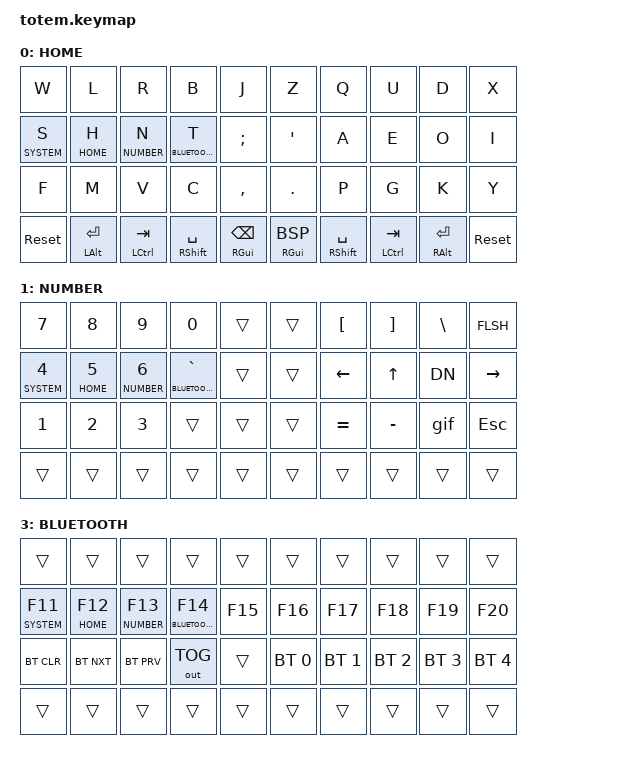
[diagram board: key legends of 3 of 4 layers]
//
//                                                        ▀▀▀▀▀     ▀▀▀▀▀          ▀▀█▀▀
//                                                        ▄▀▀▀▄  ▄  ▄▀▀▀▄  ▄  ▄▀▀▀▄  █  ▄▀▀▀▄
//                                                        █   █  █  █   █  █  █   █  █  █   █
//                                                         ▀▀▀   █   ▀▀▀   █   ▀▀▀   ▀   ▀▀▀
//                                                               █      ▄▄▄█▄▄▄    █   █  
//                                                               ▀      █  █  █     █▄█
//                                                             ▀▀▀▀▀    █  █  █      ▀
//                                                                      ▀  ▀  ▀
//
// ▄▄▄▄▄▄▄▄▄▄▄▄▄▄▄▄▄▄▄▄▄▄▄▄▄▄▄▄▄▄▄▄▄▄▄▄▄▄▄▄▄▄▄▄▄▄▄▄▄▄▄▄▄▄▄▄▄▄▄▄▄▄▄▄▄▄▄▄▄▄▄▄▄▄▄▄▄▄▄▄▄▄▄▄▄▄▄▄▄▄▄▄▄▄▄▄▄▄▄▄▄▄▄▄▄▄▄▄▄▄▄▄▄▄▄▄▄▄▄▄▄▄▄▄▄▄▄▄▄▄▄▄▄▄▄▄▄▄▄▄▄▄▄▄▄▄▄▄▄
       

#include <behaviors.dtsi>
#include <dt-bindings/zmk/keys.h>
#include <dt-bindings/zmk/bt.h>
#include <dt-bindings/zmk/outputs.h>

#define HOME 0
#define NUMBER 1
#define SYSTEM 2
#define BLUETOOTH 3

&mt {
  quick-tap-ms = <100>;
  global-quick-tap;
  flavor = "tap-preferred";
  tapping-term-ms = <170>;
};

/ {
    combos {
            compatible = "zmk,combos";
            combo_esc {
                timeout-ms = <50>;
                key-positions = <0 1>;
                bindings = <&kp ESC>;
            };
    };

    macros {
        gif: gif {
            label = "giphy";
            compatible = "zmk,behavior-macro";
            #binding-cells = <0>;
            bindings
                = <&macro_press &kp LSHFT>
                , <&macro_tap &kp N2>
                , <&macro_release &kp LSHFT>
                , <&macro_tap &kp G &kp I &kp F>
                ;
        };
    };

        keymap {
                compatible = "zmk,keymap";
// ▄▄▄▄▄▄▄▄▄▄▄▄▄▄▄▄▄▄▄▄▄▄▄▄▄▄▄▄▄▄▄▄▄▄▄▄▄▄▄▄▄▄▄▄▄▄▄▄▄▄▄▄▄▄▄▄▄▄▄▄▄▄▄▄▄▄▄▄▄▄▄▄▄▄▄▄▄▄▄▄▄▄▄▄▄▄▄▄▄▄▄▄▄▄▄▄▄▄▄▄▄▄▄▄▄▄▄▄▄▄▄▄▄▄▄▄▄▄▄▄▄▄▄▄▄▄▄▄▄▄▄▄▄▄▄▄▄▄▄▄▄▄▄▄▄▄▄▄▄

                home_layer {
// ┏━━━━━━━━━━━━━━━━━━━━━━━━━━━━━━━━━━━━━━━┓
label= "HOME"                              ;
// ┗━━━━━━━━━━━━━━━━━━━━━━━━━━━━━━━━━━━━━━━┛
//             ┏━━━━━━━━━━━┳━━━━━━━━━━━┳━━━━━━━━━━━┳━━━━━━━━━━━┳━━━━━━━━━━━┓   ┏━━━━━━━━━━━┳━━━━━━━━━━━┳━━━━━━━━━━━┳━━━━━━━━━━━┳━━━━━━━━━━━┓
//             ┃      W    ┃     L     ┃    R      ┃     B     ┃     J     ┃   ┃      Z    ┃   Q       ┃     U     ┃     D     ┃   X       ┃
//             ┣━━━━━━━━━━━╋━━━━━━━━━━━╋━━━━━━━━━━━╋━━━━━━━━━━━╋━━━━━━━━━━━┫   ┣━━━━━━━━━━━╋━━━━━━━━━━━╋━━━━━━━━━━━╋━━━━━━━━━━━╋━━━━━━━━━━━┫
//             ┃      S    ┃     H     ┃    N      ┃     T     ┃   ;       ┃   ┃    APOS   ┃   A       ┃     E     ┃     I     ┃     O     ┃
// ┏━━━━━━━━━━━╋━━━━━━━━━━━╋━━━━━━━━━━━╋━━━━━━━━━━━╋━━━━━━━━━━━╋━━━━━━━━━━━┫   ┣━━━━━━━━━━━╋━━━━━━━━━━━╋━━━━━━━━━━━╋━━━━━━━━━━━╋━━━━━━━━━━━╋━━━━━━━━━━━┓
// ┃           ┃      F    ┃     M     ┃    V      ┃     C     ┃    ,      ┃   ┃   .       ┃   P       ┃     G     ┃    K      ┃    Y      ┃           ┃
// ┗━━━━━━━━━━━┻━━━━━━━━━━━┻━━━━━━━━━━━╋━━━━━━━━━━━╋━━━━━━━━━━━╋━━━━━━━━━━━┫   ┣━━━━━━━━━━━╋━━━━━━━━━━━╋━━━━━━━━━━━╋━━━━━━━━━━━┻━━━━━━━━━━━┻━━━━━━━━━━━┛
//               sys_reset   ALT RET   ┃ LCTRL TAB ┃RSHFT SPACE┃ RGUI BSP  ┃   ┃  RGUI BSP ┃RSHFT SPACE┃ LCTRL TAB ┃ALT RET     sys_reset
//                                   ┗━━━━━━━━━━━┻━━━━━━━━━━━┻━━━━━━━━━━━┛   ┗━━━━━━━━━━━┻━━━━━━━━━━━┻━━━━━━━━━━━┛
 bindings = <
// ╷           ╷             ╷             ╷               ╷                 ╷           ╷     ╷             ╷               ╷             ╷             ╷           ╷

                &kp W          &kp L         &kp R          &kp B             &kp J             &kp Z         &kp Q           &kp U         &kp D        &kp X
                &lt SYSTEM S   &lt HOME H    &lt NUMBER N   &lt BLUETOOTH T   &kp SEMI          &kp APOS      &kp A           &kp E         &kp O        &kp I  
                &kp F          &kp M         &kp  V         &kp C             &kp COMMA         &kp DOT       &kp P           &kp G         &kp K        &kp Y
                &sys_reset     &mt LALT RET  &mt LCTRL TAB  &mt RSHFT SPACE   &mt RGUI BSPC     &mt RGUI BSP  &mt RSHFT SPACE &mt LCTRL TAB &mt RALT RET &sys_reset 
                        >;
                };

// ▄▄▄▄▄▄▄▄▄▄▄▄▄▄▄▄▄▄▄▄▄▄▄▄▄▄▄▄▄▄▄▄▄▄▄▄▄▄▄▄▄▄▄▄▄▄▄▄▄▄▄▄▄▄▄▄▄▄▄▄▄▄▄▄▄▄▄▄▄▄▄▄▄▄▄▄▄▄▄▄▄▄▄▄▄▄▄▄▄▄▄▄▄▄▄▄▄▄▄▄▄▄▄▄▄▄▄▄▄▄▄▄▄▄▄▄▄▄▄▄▄▄▄▄▄▄▄▄▄▄▄▄▄▄▄▄▄▄▄▄▄▄▄▄▄▄▄▄▄


                number_layer {
// ┏━━━━━━━━━━━━━━━━━━━━━━━━━━━━━━━━━━━━━━━┓
label= "NUMBER"                              ;
// ┗━━━━━━━━━━━━━━━━━━━━━━━━━━━━━━━━━━━━━━━┛
//             ┏━━━━━━━━━━━┳━━━━━━━━━━━┳━━━━━━━━━━━┳━━━━━━━━━━━┳━━━━━━━━━━━┓   ┏━━━━━━━━━━━┳━━━━━━━━━━━┳━━━━━━━━━━━┳━━━━━━━━━━━┳━━━━━━━━━━━┓
//             ┃     7     ┃     8     ┃     9     ┃    0      ┃   trans   ┃   ┃   trans   ┃    BKT    ┃   RBKT    ┃   BSLH    ┃   FLSH    ┃
//             ┣━━━━━━━━━━━╋━━━━━━━━━━━╋━━━━━━━━━━━╋━━━━━━━━━━━╋━━━━━━━━━━━┫   ┣━━━━━━━━━━━╋━━━━━━━━━━━╋━━━━━━━━━━━╋━━━━━━━━━━━╋━━━━━━━━━━━┫
//             ┃     4     ┃     5     ┃     6     ┃btooth/grave ┃ trans   ┃   ┃   trans   ┃   LEFT    ┃    UP     ┃    DN     ┃   RIGHT   ┃
// ┏━━━━━━━━━━━╋━━━━━━━━━━━╋━━━━━━━━━━━╋━━━━━━━━━━━╋━━━━━━━━━━━╋━━━━━━━━━━━┫   ┣━━━━━━━━━━━╋━━━━━━━━━━━╋━━━━━━━━━━━╋━━━━━━━━━━━╋━━━━━━━━━━━╋━━━━━━━━━━━┓
// ┃           ┃     1     ┃     2     ┃     3     ┃   trans   ┃   trans   ┃   ┃   trans   ┃   EQUAL   ┃   MINUS   ┃     &gif  ┃    ESC    ┃           ┃
// ┗━━━━━━━━━━━┻━━━━━━━━━━━┻━━━━━━━━━━━╋━━━━━━━━━━━╋━━━━━━━━━━━╋━━━━━━━━━━━┫   ┣━━━━━━━━━━━╋━━━━━━━━━━━╋━━━━━━━━━━━╋━━━━━━━━━━━┻━━━━━━━━━━━┻━━━━━━━━━━━┛
//                 trans      trans    ┃   trans   ┃   trans   ┃   trans   ┃   ┃   trans   ┃   trans   ┃   trans   ┃   trans      trans
//                                     ┗━━━━━━━━━━━┻━━━━━━━━━━━┻━━━━━━━━━━━┛   ┗━━━━━━━━━━━┻━━━━━━━━━━━┻━━━━━━━━━━━┛
 bindings = <
// ╷           ╷             ╷            ╷              ╷                    ╷      ╷  ╷          ╷          ╷          ╷           ╷           ╷

                &kp N7        &kp N8       &kp N9         &kp N0               &trans   &trans    &kp LBKT   &kp RBKT   &kp BSLH   &kp FLSH 
                &lt SYSTEM N4 &lt HOME N5  &lt NUMBER N6  &lt BLUETOOTH GRAVE  &trans   &trans    &kp LEFT   &kp UP     &kp DN     &kp RIGHT  
                &kp N1        &kp N2       &kp N3         &trans               &trans   &trans    &kp EQUAL  &kp MINUS  &gif       &kp ESC            
                &trans        &trans       &trans         &trans               &trans   &trans    &trans     &trans     &trans     &trans 
                        >;
                };

// ▄▄▄▄▄▄▄▄▄▄▄▄▄▄▄▄▄▄▄▄▄▄▄▄▄▄▄▄▄▄▄▄▄▄▄▄▄▄▄▄▄▄▄▄▄▄▄▄▄▄▄▄▄▄▄▄▄▄▄▄▄▄▄▄▄▄▄▄▄▄▄▄▄▄▄▄▄▄▄▄▄▄▄▄▄▄▄▄▄▄▄▄▄▄▄▄▄▄▄▄▄▄▄▄▄▄▄▄▄▄▄▄▄▄▄▄▄▄▄▄▄▄▄▄▄▄▄▄▄▄▄▄▄▄▄▄▄▄▄▄▄▄▄▄▄▄▄▄▄


                system_layer {
// ┏━━━━━━━━━━━━━━━━━━━━━━━━━━━━━━━━━━━━━━━┓
label= "SYSTEM"                               ;
// ┗━━━━━━━━━━━━━━━━━━━━━━━━━━━━━━━━━━━━━━━┛
//             ┏━━━━━━━━━━━┳━━━━━━━━━━━┳━━━━━━━━━━━┳━━━━━━━━━━━┳━━━━━━━━━━━┓   ┏━━━━━━━━━━━┳━━━━━━━━━━━┳━━━━━━━━━━━┳━━━━━━━━━━━┳━━━━━━━━━━━┓
//             ┃ &kp PG UP ┃ &kp PG DN ┃   &trans  ┃       &trans        &trans  ┃  ┃&trans┃ &kpC_MUTE ┃&kp C_VOL_DN┃ &kp C_VOL_UP ┃ &trans
//             ┣━━━━━━━━━━━╋━━━━━━━━━━━╋━━━━━━━━━━━╋━━━━━━━━━━━╋━━━━━━━━━━━┫   ┣━━━━━━━━━━━╋━━━━━━━━━━━╋━━━━━━━━━━━╋━━━━━━━━━━━╋━━━━━━━━━━━┫
//             ┃ SYSTEM F1 ┃  HOME F2  ┃ NUMBER F3 ┃&lt BLUETOOTH  F4    &kp F5  ┃  ┃&kp F6┃    &kp F7 ┃   &kp F8  ┃  &kp F9   ┃  &kp F10  ┃
// ┏━━━━━━━━━━━╋━━━━━━━━━━━╋━━━━━━━━━━━╋━━━━━━━━━━━╋━━━━━━━━━━━╋━━━━━━━━━━━┫   ┣━━━━━━━━━━━╋━━━━━━━━━━━╋━━━━━━━━━━━╋━━━━━━━━━━━╋━━━━━━━━━━━╋━━━━━━━━━━━┓
// ┃           ┃kp C_BRI_UP┃C_BRI_DN   ┃ &trans    ┃       &trans        &trans  ┃  ┃&trans┃  &trans   ┃  &trans   ┃  &trans   ┃    ESC    ┃           ┃
// ┗━━━━━━━━━━━┻━━━━━━━━━━━┻━━━━━━━━━━━╋━━━━━━━━━━━╋━━━━━━━━━━━╋━━━━━━━━━━━┫   ┣━━━━━━━━━━━╋━━━━━━━━━━━╋━━━━━━━━━━━╋━━━━━━━━━━━┻━━━━━━━━━━━┻━━━━━━━━━━━┛
//                 &trans     &trans   ┃   &trans  ┃        &trans       &trans  ┃  ┃trans ┃   &trans  ┃   &trans  ┃&trans        &trans
//                                     ┗━━━━━━━━━━━┻━━━━━━━━━━━┻━━━━━━━━━━━┛   ┗━━━━━━━━━━━┻━━━━━━━━━━━┻━━━━━━━━━━━┛
 bindings = <
// ╷           ╷              ╷             ╷              ╷                   ╷        ╷   ╷           ╷              ╷             ╷             ╷           ╷           ╷

                &kp PG UP       &kp PG DN    &trans         &trans               &trans      &trans      &kp C_MUTE     &kp C_VOL_DN  &kp C_VOL_UP  &trans      
                &lt SYSTEM F1   &lt HOME F2  &lt NUMBER F3  &lt BLUETOOTH  F4    &kp F5      &kp F6      &kp F7         &kp F8        &kp F9        &kp F10
                &kp C_BRI_UP    &kp C_BRI_DN &trans         &trans               &trans      &trans      &trans         &trans        &trans        &kp ESC            
                &trans          &trans       &trans         &trans               &trans      &trans      &trans         &trans        &trans        &trans 
                        >;
                };

// ▄▄▄▄▄▄▄▄▄▄▄▄▄▄▄▄▄▄▄▄▄▄▄▄▄▄▄▄▄▄▄▄▄▄▄▄▄▄▄▄▄▄▄▄▄▄▄▄▄▄▄▄▄▄▄▄▄▄▄▄▄▄▄▄▄▄▄▄▄▄▄▄▄▄▄▄▄▄▄▄▄▄▄▄▄▄▄▄▄▄▄▄▄▄▄▄▄▄▄▄▄▄▄▄▄▄▄▄▄▄▄▄▄▄▄▄▄▄▄▄▄▄▄▄▄▄▄▄▄▄▄▄▄▄▄▄▄▄▄▄▄▄▄▄▄▄▄▄▄


                bluetooth_layer {
// ┏━━━━━━━━━━━━━━━━━━━━━━━━━━━━━━━━━━━━━━━┓
label= "BLUETOOTH"                               ;
// ┗━━━━━━━━━━━━━━━━━━━━━━━━━━━━━━━━━━━━━━━┛
//             ┏━━━━━━━━━━━┳━━━━━━━━━━━┳━━━━━━━━━━━┳━━━━━━━━━━━┳━━━━━━━━━━━┓   ┏━━━━━━━━━━━┳━━━━━━━━━━━┳━━━━━━━━━━━┳━━━━━━━━━━━┳━━━━━━━━━━━┓
//             ┃   &trans  ┃  &trans   ┃   &trans  ┃  &trans   ┃   &trans  ┃   ┃    &trans  ┃   &trans   ┃   &trans   ┃   &trans   ┃   &trans   ┃
//             ┣━━━━━━━━━━━╋━━━━━━━━━━━╋━━━━━━━━━━━╋━━━━━━━━━━━╋━━━━━━━━━━━┫   ┣━━━━━━━━━━━╋━━━━━━━━━━━╋━━━━━━━━━━━╋━━━━━━━━━━━╋━━━━━━━━━━━┫
//             ┃SYSTEM F11 ┃  HOME F12 ┃ NUMBER F13┃ BTOOTH F14┃  &kp F15  ┃   ┃  &kp F16   ┃  &kp F17   ┃  &kp F18   ┃  &kp F19   ┃   &kp F20  ┃
// ┏━━━━━━━━━━━╋━━━━━━━━━━━╋━━━━━━━━━━━╋━━━━━━━━━━━╋━━━━━━━━━━━╋━━━━━━━━━━━┫   ┣━━━━━━━━━━━╋━━━━━━━━━━━╋━━━━━━━━━━━╋━━━━━━━━━━━╋━━━━━━━━━━━╋━━━━━━━━━━━┓
// ┃           ┃ &kp BT_CLR┃  BT_NXT   ┃&kp BT_PRV ┃  OUT_TOG  ┃   trans   ┃   ┃&bt BT_SEL 0┃&bt BT_SEL 1┃&bt BT_SEL 2┃&bt BT_SEL 3┃&bt BT_SEL 4┃          ┃
// ┗━━━━━━━━━━━┻━━━━━━━━━━━┻━━━━━━━━━━━╋━━━━━━━━━━━╋━━━━━━━━━━━╋━━━━━━━━━━━┫   ┣━━━━━━━━━━━╋━━━━━━━━━━━╋━━━━━━━━━━━╋━━━━━━━━━━━┻━━━━━━━━━━━┻━━━━━━━━━━━┛
//                 &trans     &trans   ┃   &trans  ┃   &trans  ┃   &trans  ┃   ┃   &trans   ┃   &trans   ┃   &trans   ┃   &trans       &trans 
//                                     ┗━━━━━━━━━━━┻━━━━━━━━━━━┻━━━━━━━━━━━┛   ┗━━━━━━━━━━━┻━━━━━━━━━━━┻━━━━━━━━━━━┛
 bindings = <
// ╷           ╷               ╷            ╷               ╷                   ╷        ╷   ╷            ╷            ╷            ╷            ╷           ╷           ╷

                &trans          &trans       &trans          &trans              &trans       &trans       &trans       &trans       &trans       &trans
                &lt SYSTEM F11  &lt HOME F12 &lt NUMBER F13  &lt BLUETOOTH F14   &kp F15      &kp F16      &kp F17      &kp F18      &kp F19      &kp F20
                &bt BT_CLR      &bt BT_NXT   &bt BT_PRV      &out OUT_TOG        &trans       &bt BT_SEL 0 &bt BT_SEL 1 &bt BT_SEL 2 &bt BT_SEL 3 &bt BT_SEL 4           
                &trans          &trans       &trans          &trans              &trans       &trans       &trans       &trans       &trans       &trans 
                        >;
                };
        };
};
